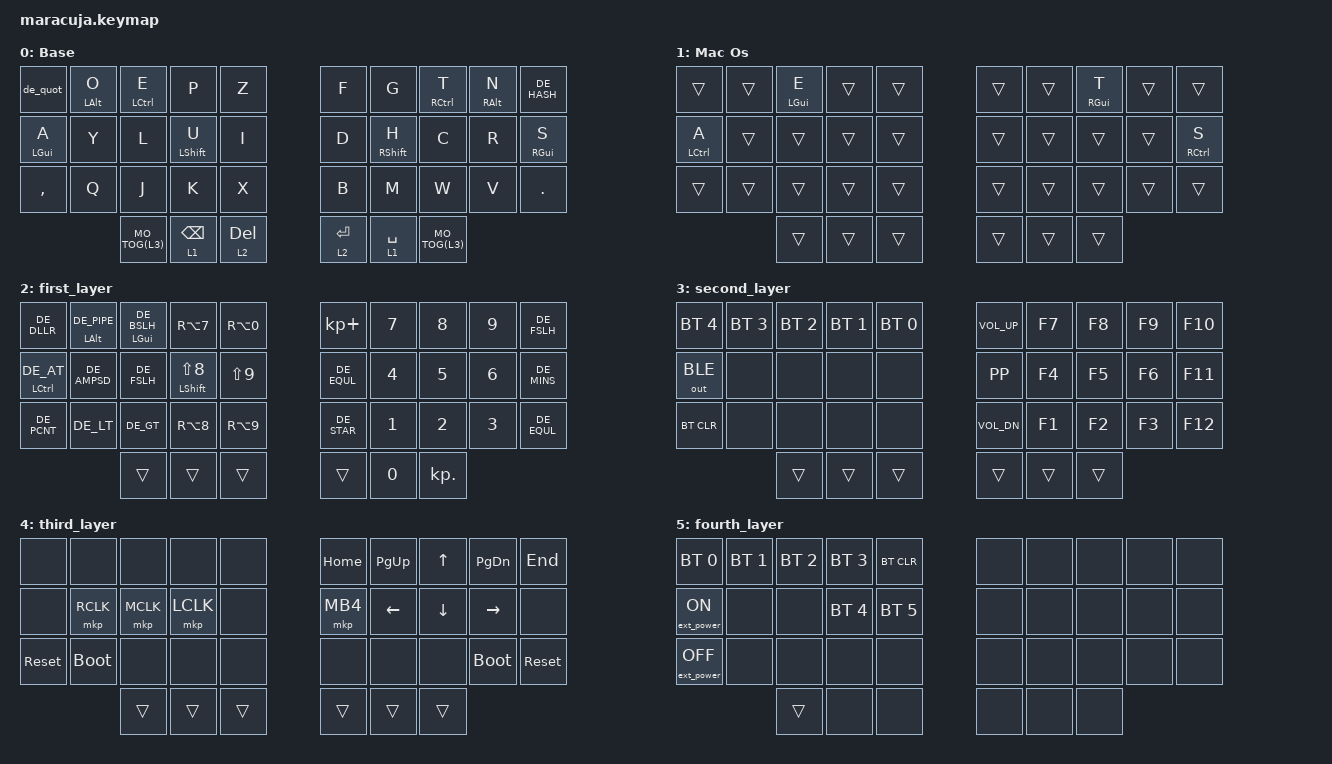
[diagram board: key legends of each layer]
/*
 * Copyright (c) 2020 The ZMK Contributors
 *
 * SPDX-License-Identifier: MIT
 */

#include <behaviors.dtsi>
#include <dt-bindings/zmk/keys.h>
#include <dt-bindings/zmk/bt.h>
#include <dt-bindings/zmk/outputs.h>
#include <dt-bindings/zmk/ext_power.h>
#include <dt-bindings/zmk/mouse.h>

#define DEFAULT 0
#define MAC 1
#define L1 2  // NUMBERs, Special Chars
#define L2 3  // F1-12..
#define L3 4  // NAVI
#define L4 5  // BLUETOOTH

#define AUML APOS
#define OUML SEMI
#define UUML LBKT
#define DE_SS MINUS
#define DE_MINS SLASH
#define DE_DLLR LS(N4)
#define DE_PCNT LS(N5)
#define DE_AMPSD LS(N6)
#define DE_FSLH LS(N7)
#define DE_PLUS LS(RBRC)
#define DE_STAR RBRC
#define DE_EQUL LS(N0)
#define DE_AT RA(Q)
#define DE_HASH BSLH
#define DE_LT GRAVE //NON_US_BSLH
#define DE_GT LS(GRAVE) //LS(NON_US_BSLH)
#define DE_PIPE RA(GRAVE)
#define DE_BSLH RA(MINUS)
#define DE_EXCL LS(N1)

&lt {
    tapping-term-ms = <250>;
    quick_tap_ms = <150>;
    flavor = "tap-preferred";
};

&caps_word {
    continue-list = <UNDERSCORE DE_MINS BSPC DELETE>;
};

&mt {
  quick-tap-ms = <200>;
};

#define MO_TOG(layer) &mo_tog layer layer   // Macro to apply momentary-layer-on-hold/toggle-layer-on-tap to a specific layer

/ {

  behaviors {
    hm: homerow_mods {
        compatible = "zmk,behavior-hold-tap";
        label = "HOMEROW_MODS";
        require-prior-idle-ms = <250>;
        #binding-cells = <2>;
        bindings = <&kp>, <&kp>;
        tapping-term-ms = <200>;
        flavor = "tap-preferred";
    };
    hsl: homerow_shift_l {
        compatible = "zmk,behavior-hold-tap";
        label = "HOMEROW_SHIFT_L";
        #binding-cells = <2>;
        bindings = <&kp>, <&kp>;
        tapping-term-ms = <160>;
        flavor = "balanced";
        hold-trigger-key-positions = <5 6 7 8 9 15 16 17 18 19 25 26 27 28 29 33 34 35>;
    };
    hsr: homerow_shift_r {
        compatible = "zmk,behavior-hold-tap";
        label = "HOMEROW_SHIFT_R";
        #binding-cells = <2>;
        bindings = <&kp>, <&kp>;
        tapping-term-ms = <160>;
        flavor = "balanced";
        hold-trigger-key-positions = <0 1 2 3 4 10 11 12 13 14 20 21 22 23 24 30 31 32>;
    };
    mo_tog: behavior_mo_tog {
        compatible = "zmk,behavior-hold-tap";
        label = "mo_tog";
        #binding-cells = <2>;
        flavor = "hold-preferred";
        tapping-term-ms = <200>;
        bindings = <&mo>, <&tog>;
    };
    de_quot: german_quote_doublequote {
        compatible = "zmk,behavior-mod-morph";
        label = "DE_QUOTES";
        #binding-cells = <0>;
        bindings = <&kp LS(BSLH)>, <&kp LS(N2)>;
        mods = <(MOD_LSFT|MOD_RSFT)>;
    };
  };

  combos {
    compatible = "zmk,combos";

    #define COMBO(NAME, BINDINGS, KEYPOS, PREIDLE) \
      combo_##NAME { \
        bindings = <BINDINGS>; \
        key-positions = <KEYPOS>; \
        require-prior-idle-ms = <PREIDLE>; \
      };

    /*
      ╭─────────────────────╮  ╭─────────────────────╮
      │   0   1   2   3   4 │  │  5   6   7   8  9   │
      │  10  11  12  13  14 │  │ 15  16  17  18  19  │
      │  20  21  22  23  24 │  | 25  26  27  28  29  │
      ╰────────╮ 30  31  32 │  │ 33  34  35 ╭────────╯
               ╰────────────╯  ╰────────────╯
    */

    COMBO(auml, &kp AUML, 10 12, 0)
    COMBO(ouml, &kp OUML, 1 12, 0)
    COMBO(uuml, &kp UUML, 12 13, 0)
    COMBO(szuml, &kp DE_SS, 17 19, 0)
    COMBO(excl, &kp DE_EXCL, 21 22, 20)
    COMBO(qustm, &kp LS(MINUS), 27 28, 20)

    COMBO(caps_word, &caps_word, 13 16, 250)
    COMBO(esc, &kp ESC, 1 2, 250)
    COMBO(tab, &kp TAB, 11 12, 250)
    COMBO(osx, &tog MAC, 1 24, 250)
    COMBO(numlock, &tog L1, 26 27 28, 250)
    
  };

  keymap {
    compatible = "zmk,keymap";

    default_layer {
      label = "Base";
      bindings = <
   &de_quot     &hm LALT O &hm LCTL E &kp P        &kp Z                &kp F        &kp G        &hm RCTL T   &hm RALT N   &kp DE_HASH
   &hm LGUI A   &kp Y      &kp L      &hsl LSHFT U &kp I                &kp D        &hsr RSHFT H &kp C        &kp R        &hm RGUI S
   &kp COMMA    &kp Q      &kp J      &kp K        &kp X                &kp B        &kp M        &kp W        &kp V        &kp DOT
                           MO_TOG(L3) &lt L1 BSPC  &lt L2 DEL           &lt L2 ENTER &lt L1 SPACE MO_TOG(L3)
      >;
    };

    mac_layer {
      label = "Mac Os";
      bindings = <
   &trans     &trans   &hm LGUI E  &trans   &trans            &trans   &trans  &hm RGUI T  &trans  &trans
   &hm LCTL A &trans   &trans      &trans   &trans            &trans   &trans  &trans      &trans  &hm RCTL S
   &trans     &trans   &trans      &trans   &trans            &trans   &trans  &trans      &trans  &trans
                       &trans      &trans   &trans            &trans   &trans  &trans
      >;
    };

    first_layer {
      bindings = <
   &kp DE_DLLR    &hm LALT DE_PIPE &hm LGUI DE_BSLH &kp RA(N7)        &kp RA(N0)             &kp KP_PLUS  &kp N7    &kp N8      &kp N9     &kp DE_FSLH
   &hm LCTL DE_AT &kp DE_AMPSD     &kp DE_FSLH      &hsl LSHFT LS(N8) &kp LS(N9)             &kp DE_EQUL  &kp N4    &kp N5      &kp N6     &kp DE_MINS
   &kp DE_PCNT    &kp DE_LT        &kp DE_GT        &kp RA(N8)        &kp RA(N9)             &kp DE_STAR  &kp N1    &kp N2      &kp N3     &kp DE_EQUL
                                   &trans           &trans            &trans                 &trans       &kp N0    &kp KP_DOT
      >;
    };

    second_layer {
      bindings = <
   &bt BT_SEL 4 &bt BT_SEL 3 &bt BT_SEL 2 &bt BT_SEL 1 &bt BT_SEL 0         &kp K_VOL_UP &kp F7   &kp F8   &kp F9    &kp F10        
   &out OUT_BLE &none        &none        &none        &none                &kp K_PP     &kp F4   &kp F5   &kp F6    &kp F11
   &bt BT_CLR   &none        &none        &none        &none                &kp K_VOL_DN &kp F1   &kp F2   &kp F3    &kp F12
                             &trans       &trans       &trans               &trans       &trans       &trans
      >;
    };

    third_layer {
      bindings = <
   &none       &none        &none        &none        &none                &kp HOME &kp PG_UP &kp UP   &kp PG_DN   &kp END
   &none       &mkp RCLK    &mkp MCLK    &mkp LCLK    &none                &mkp MB4 &kp LEFT  &kp DOWN &kp RIGHT   &none  
   &sys_reset  &bootloader  &none        &none        &none                &none    &none     &none    &bootloader &sys_reset
                            &trans       &trans       &trans               &trans   &trans    &trans
      >;
    };

    fourth_layer {
      bindings = <
   &bt BT_SEL 0 &bt BT_SEL 1 &bt BT_SEL 2 &bt BT_SEL 3 &bt BT_CLR           &none        &none        &none        &none        &none
   &ext_power EP_ON &none        &none        &bt BT_SEL 4  &bt BT_SEL 5    &none        &none        &none        &none        &none
   &ext_power EP_OFF &none       &none        &none        &none            &none        &none        &none        &none        &none
                                 &trans       &none        &none            &none        &none        &none
      >;
    };

  };
};

